VERSION ""

NS_ :

BS_:

BU_: Reserve2 SS_WT4 SS_WT3 SS_WT2 SS_WT1 SS_WP2 SS_WP1 SS_WF SS_SA SS_RTDS SS_DFR SS_DFL SS_DBR SS_DBL VCU User Reserve1 Telemetry SteeringWheel SS_BL SmartSensor PIC ISA_Scale Distri Dashboard AMS AclrGPS
VAL_TABLE_ AliveSignal 1 "ONLINE" 0 "OFFLINE" ;

BO_ 512 AMS_Status: 5 AMS
 SG_ Cell_OV_288 m23 : 39|1@0+ (1,0) [0|0] ""  VCU
 SG_ Cell_UV_288 m23 : 38|1@0+ (1,0) [0|0] ""  VCU
 SG_ Cell_OV_287 m23 : 37|1@0+ (1,0) [0|0] ""  VCU
 SG_ Cell_UV_287 m23 : 36|1@0+ (1,0) [0|0] ""  VCU
 SG_ Cell_OV_286 m23 : 35|1@0+ (1,0) [0|0] ""  VCU
 SG_ Cell_UV_286 m23 : 34|1@0+ (1,0) [0|0] ""  VCU
 SG_ Cell_OV_285 m23 : 33|1@0+ (1,0) [0|0] ""  VCU
 SG_ Cell_UV_285 m23 : 32|1@0+ (1,0) [0|0] ""  VCU
 SG_ Cell_OV_284 m23 : 31|1@0+ (1,0) [0|0] ""  VCU
 SG_ Cell_UV_284 m23 : 30|1@0+ (1,0) [0|0] ""  VCU
 SG_ Cell_OV_283 m23 : 29|1@0+ (1,0) [0|0] ""  VCU
 SG_ Cell_UV_283 m23 : 28|1@0+ (1,0) [0|0] ""  VCU
 SG_ Cell_OV_282 m23 : 27|1@0+ (1,0) [0|0] ""  VCU
 SG_ Cell_UV_282 m23 : 26|1@0+ (1,0) [0|0] ""  VCU
 SG_ Cell_OV_281 m23 : 25|1@0+ (1,0) [0|0] ""  VCU
 SG_ Cell_UV_281 m23 : 24|1@0+ (1,0) [0|0] ""  VCU
 SG_ Cell_OV_280 m23 : 23|1@0+ (1,0) [0|0] ""  VCU
 SG_ Cell_UV_280 m23 : 22|1@0+ (1,0) [0|0] ""  VCU
 SG_ Cell_OV_279 m23 : 21|1@0+ (1,0) [0|0] ""  VCU
 SG_ Cell_UV_279 m23 : 20|1@0+ (1,0) [0|0] ""  VCU
 SG_ Cell_OV_278 m23 : 19|1@0+ (1,0) [0|0] ""  VCU
 SG_ Cell_UV_278 m23 : 18|1@0+ (1,0) [0|0] ""  VCU
 SG_ Cell_OV_277 m23 : 17|1@0+ (1,0) [0|0] ""  VCU
 SG_ Cell_UV_277 m23 : 16|1@0+ (1,0) [0|0] ""  VCU
 SG_ Cell_OV_276 m22 : 39|1@0+ (1,0) [0|0] ""  VCU
 SG_ Cell_UV_276 m22 : 38|1@0+ (1,0) [0|0] ""  VCU
 SG_ Cell_OV_275 m22 : 37|1@0+ (1,0) [0|0] ""  VCU
 SG_ Cell_UV_275 m22 : 36|1@0+ (1,0) [0|0] ""  VCU
 SG_ Cell_OV_274 m22 : 35|1@0+ (1,0) [0|0] ""  VCU
 SG_ Cell_UV_274 m22 : 34|1@0+ (1,0) [0|0] ""  VCU
 SG_ Cell_OV_273 m22 : 33|1@0+ (1,0) [0|0] ""  VCU
 SG_ Cell_UV_273 m22 : 32|1@0+ (1,0) [0|0] ""  VCU
 SG_ Cell_OV_272 m22 : 31|1@0+ (1,0) [0|0] ""  VCU
 SG_ Cell_UV_272 m22 : 30|1@0+ (1,0) [0|0] ""  VCU
 SG_ Cell_OV_271 m22 : 29|1@0+ (1,0) [0|0] ""  VCU
 SG_ Cell_UV_271 m22 : 28|1@0+ (1,0) [0|0] ""  VCU
 SG_ Cell_OV_270 m22 : 27|1@0+ (1,0) [0|0] ""  VCU
 SG_ Cell_UV_270 m22 : 26|1@0+ (1,0) [0|0] ""  VCU
 SG_ Cell_OV_269 m22 : 25|1@0+ (1,0) [0|0] ""  VCU
 SG_ Cell_UV_269 m22 : 24|1@0+ (1,0) [0|0] ""  VCU
 SG_ Cell_OV_268 m22 : 23|1@0+ (1,0) [0|0] ""  VCU
 SG_ Cell_UV_268 m22 : 22|1@0+ (1,0) [0|0] ""  VCU
 SG_ Cell_OV_267 m22 : 21|1@0+ (1,0) [0|0] ""  VCU
 SG_ Cell_UV_267 m22 : 20|1@0+ (1,0) [0|0] ""  VCU
 SG_ Cell_OV_266 m22 : 19|1@0+ (1,0) [0|0] ""  VCU
 SG_ Cell_UV_266 m22 : 18|1@0+ (1,0) [0|0] ""  VCU
 SG_ Cell_OV_265 m22 : 17|1@0+ (1,0) [0|0] ""  VCU
 SG_ Cell_UV_265 m22 : 16|1@0+ (1,0) [0|0] ""  VCU
 SG_ Cell_OV_264 m21 : 39|1@0+ (1,0) [0|0] ""  VCU
 SG_ Cell_UV_264 m21 : 38|1@0+ (1,0) [0|0] ""  VCU
 SG_ Cell_OV_263 m21 : 37|1@0+ (1,0) [0|0] ""  VCU
 SG_ Cell_UV_263 m21 : 36|1@0+ (1,0) [0|0] ""  VCU
 SG_ Cell_OV_262 m21 : 35|1@0+ (1,0) [0|0] ""  VCU
 SG_ Cell_UV_262 m21 : 34|1@0+ (1,0) [0|0] ""  VCU
 SG_ Cell_OV_261 m21 : 33|1@0+ (1,0) [0|0] ""  VCU
 SG_ Cell_UV_261 m21 : 32|1@0+ (1,0) [0|0] ""  VCU
 SG_ Cell_OV_260 m21 : 31|1@0+ (1,0) [0|0] ""  VCU
 SG_ Cell_UV_260 m21 : 30|1@0+ (1,0) [0|0] ""  VCU
 SG_ Cell_OV_259 m21 : 29|1@0+ (1,0) [0|0] ""  VCU
 SG_ Cell_UV_259 m21 : 28|1@0+ (1,0) [0|0] ""  VCU
 SG_ Cell_OV_258 m21 : 27|1@0+ (1,0) [0|0] ""  VCU
 SG_ Cell_UV_258 m21 : 26|1@0+ (1,0) [0|0] ""  VCU
 SG_ Cell_OV_257 m21 : 25|1@0+ (1,0) [0|0] ""  VCU
 SG_ Cell_UV_257 m21 : 24|1@0+ (1,0) [0|0] ""  VCU
 SG_ Cell_OV_256 m21 : 23|1@0+ (1,0) [0|0] ""  VCU
 SG_ Cell_UV_256 m21 : 22|1@0+ (1,0) [0|0] ""  VCU
 SG_ Cell_OV_255 m21 : 21|1@0+ (1,0) [0|0] ""  VCU
 SG_ Cell_UV_255 m21 : 20|1@0+ (1,0) [0|0] ""  VCU
 SG_ Cell_OV_254 m21 : 19|1@0+ (1,0) [0|0] ""  VCU
 SG_ Cell_UV_254 m21 : 18|1@0+ (1,0) [0|0] ""  VCU
 SG_ Cell_OV_253 m21 : 17|1@0+ (1,0) [0|0] ""  VCU
 SG_ Cell_UV_253 m21 : 16|1@0+ (1,0) [0|0] ""  VCU
 SG_ Cell_OV_252 m20 : 39|1@0+ (1,0) [0|0] ""  VCU
 SG_ Cell_UV_252 m20 : 38|1@0+ (1,0) [0|0] ""  VCU
 SG_ Cell_OV_251 m20 : 37|1@0+ (1,0) [0|0] ""  VCU
 SG_ Cell_UV_251 m20 : 36|1@0+ (1,0) [0|0] ""  VCU
 SG_ Cell_OV_250 m20 : 35|1@0+ (1,0) [0|0] ""  VCU
 SG_ Cell_UV_250 m20 : 34|1@0+ (1,0) [0|0] ""  VCU
 SG_ Cell_OV_249 m20 : 33|1@0+ (1,0) [0|0] ""  VCU
 SG_ Cell_UV_249 m20 : 32|1@0+ (1,0) [0|0] ""  VCU
 SG_ Cell_OV_248 m20 : 31|1@0+ (1,0) [0|0] ""  VCU
 SG_ Cell_UV_248 m20 : 30|1@0+ (1,0) [0|0] ""  VCU
 SG_ Cell_OV_247 m20 : 29|1@0+ (1,0) [0|0] ""  VCU
 SG_ Cell_UV_247 m20 : 28|1@0+ (1,0) [0|0] ""  VCU
 SG_ Cell_OV_246 m20 : 27|1@0+ (1,0) [0|0] ""  VCU
 SG_ Cell_UV_246 m20 : 26|1@0+ (1,0) [0|0] ""  VCU
 SG_ Cell_OV_245 m20 : 25|1@0+ (1,0) [0|0] ""  VCU
 SG_ Cell_UV_245 m20 : 24|1@0+ (1,0) [0|0] ""  VCU
 SG_ Cell_OV_244 m20 : 23|1@0+ (1,0) [0|0] ""  VCU
 SG_ Cell_UV_244 m20 : 22|1@0+ (1,0) [0|0] ""  VCU
 SG_ Cell_OV_243 m20 : 21|1@0+ (1,0) [0|0] ""  VCU
 SG_ Cell_UV_243 m20 : 20|1@0+ (1,0) [0|0] ""  VCU
 SG_ Cell_OV_242 m20 : 19|1@0+ (1,0) [0|0] ""  VCU
 SG_ Cell_UV_242 m20 : 18|1@0+ (1,0) [0|0] ""  VCU
 SG_ Cell_OV_241 m20 : 17|1@0+ (1,0) [0|0] ""  VCU
 SG_ Cell_UV_241 m20 : 16|1@0+ (1,0) [0|0] ""  VCU
 SG_ Cell_OV_240 m19 : 39|1@0+ (1,0) [0|0] ""  VCU
 SG_ Cell_UV_240 m19 : 38|1@0+ (1,0) [0|0] ""  VCU
 SG_ Cell_OV_239 m19 : 37|1@0+ (1,0) [0|0] ""  VCU
 SG_ Cell_UV_239 m19 : 36|1@0+ (1,0) [0|0] ""  VCU
 SG_ Cell_OV_238 m19 : 35|1@0+ (1,0) [0|0] ""  VCU
 SG_ Cell_UV_238 m19 : 34|1@0+ (1,0) [0|0] ""  VCU
 SG_ Cell_OV_237 m19 : 33|1@0+ (1,0) [0|0] ""  VCU
 SG_ Cell_UV_237 m19 : 32|1@0+ (1,0) [0|0] ""  VCU
 SG_ Cell_OV_236 m19 : 31|1@0+ (1,0) [0|0] ""  VCU
 SG_ Cell_UV_236 m19 : 30|1@0+ (1,0) [0|0] ""  VCU
 SG_ Cell_OV_235 m19 : 29|1@0+ (1,0) [0|0] ""  VCU
 SG_ Cell_UV_235 m19 : 28|1@0+ (1,0) [0|0] ""  VCU
 SG_ Cell_OV_234 m19 : 27|1@0+ (1,0) [0|0] ""  VCU
 SG_ Cell_UV_234 m19 : 26|1@0+ (1,0) [0|0] ""  VCU
 SG_ Cell_OV_233 m19 : 25|1@0+ (1,0) [0|0] ""  VCU
 SG_ Cell_UV_233 m19 : 24|1@0+ (1,0) [0|0] ""  VCU
 SG_ Cell_OV_232 m19 : 23|1@0+ (1,0) [0|0] ""  VCU
 SG_ Cell_UV_232 m19 : 22|1@0+ (1,0) [0|0] ""  VCU
 SG_ Cell_OV_231 m19 : 21|1@0+ (1,0) [0|0] ""  VCU
 SG_ Cell_UV_231 m19 : 20|1@0+ (1,0) [0|0] ""  VCU
 SG_ Cell_OV_230 m19 : 19|1@0+ (1,0) [0|0] ""  VCU
 SG_ Cell_UV_230 m19 : 18|1@0+ (1,0) [0|0] ""  VCU
 SG_ Cell_OV_229 m19 : 17|1@0+ (1,0) [0|0] ""  VCU
 SG_ Cell_UV_229 m19 : 16|1@0+ (1,0) [0|0] ""  VCU
 SG_ Cell_OV_228 m18 : 39|1@0+ (1,0) [0|0] ""  VCU
 SG_ Cell_UV_228 m18 : 38|1@0+ (1,0) [0|0] ""  VCU
 SG_ Cell_OV_227 m18 : 37|1@0+ (1,0) [0|0] ""  VCU
 SG_ Cell_UV_227 m18 : 36|1@0+ (1,0) [0|0] ""  VCU
 SG_ Cell_OV_226 m18 : 35|1@0+ (1,0) [0|0] ""  VCU
 SG_ Cell_UV_226 m18 : 34|1@0+ (1,0) [0|0] ""  VCU
 SG_ Cell_OV_225 m18 : 33|1@0+ (1,0) [0|0] ""  VCU
 SG_ Cell_UV_225 m18 : 32|1@0+ (1,0) [0|0] ""  VCU
 SG_ Cell_OV_224 m18 : 31|1@0+ (1,0) [0|0] ""  VCU
 SG_ Cell_UV_224 m18 : 30|1@0+ (1,0) [0|0] ""  VCU
 SG_ Cell_OV_223 m18 : 29|1@0+ (1,0) [0|0] ""  VCU
 SG_ Cell_UV_223 m18 : 28|1@0+ (1,0) [0|0] ""  VCU
 SG_ Cell_OV_222 m18 : 27|1@0+ (1,0) [0|0] ""  VCU
 SG_ Cell_UV_222 m18 : 26|1@0+ (1,0) [0|0] ""  VCU
 SG_ Cell_OV_221 m18 : 25|1@0+ (1,0) [0|0] ""  VCU
 SG_ Cell_UV_221 m18 : 24|1@0+ (1,0) [0|0] ""  VCU
 SG_ Cell_OV_220 m18 : 23|1@0+ (1,0) [0|0] ""  VCU
 SG_ Cell_UV_220 m18 : 22|1@0+ (1,0) [0|0] ""  VCU
 SG_ Cell_OV_219 m18 : 21|1@0+ (1,0) [0|0] ""  VCU
 SG_ Cell_UV_219 m18 : 20|1@0+ (1,0) [0|0] ""  VCU
 SG_ Cell_OV_218 m18 : 19|1@0+ (1,0) [0|0] ""  VCU
 SG_ Cell_UV_218 m18 : 18|1@0+ (1,0) [0|0] ""  VCU
 SG_ Cell_OV_217 m18 : 17|1@0+ (1,0) [0|0] ""  VCU
 SG_ Cell_UV_217 m18 : 16|1@0+ (1,0) [0|0] ""  VCU
 SG_ Cell_OV_216 m17 : 39|1@0+ (1,0) [0|0] ""  VCU
 SG_ Cell_UV_216 m17 : 38|1@0+ (1,0) [0|0] ""  VCU
 SG_ Cell_OV_215 m17 : 37|1@0+ (1,0) [0|0] ""  VCU
 SG_ Cell_UV_215 m17 : 36|1@0+ (1,0) [0|0] ""  VCU
 SG_ Cell_OV_214 m17 : 35|1@0+ (1,0) [0|0] ""  VCU
 SG_ Cell_UV_214 m17 : 34|1@0+ (1,0) [0|0] ""  VCU
 SG_ Cell_OV_213 m17 : 33|1@0+ (1,0) [0|0] ""  VCU
 SG_ Cell_UV_213 m17 : 32|1@0+ (1,0) [0|0] ""  VCU
 SG_ Cell_OV_212 m17 : 31|1@0+ (1,0) [0|0] ""  VCU
 SG_ Cell_UV_212 m17 : 30|1@0+ (1,0) [0|0] ""  VCU
 SG_ Cell_OV_211 m17 : 29|1@0+ (1,0) [0|0] ""  VCU
 SG_ Cell_UV_211 m17 : 28|1@0+ (1,0) [0|0] ""  VCU
 SG_ Cell_OV_210 m17 : 27|1@0+ (1,0) [0|0] ""  VCU
 SG_ Cell_UV_210 m17 : 26|1@0+ (1,0) [0|0] ""  VCU
 SG_ Cell_OV_209 m17 : 25|1@0+ (1,0) [0|0] ""  VCU
 SG_ Cell_UV_209 m17 : 24|1@0+ (1,0) [0|0] ""  VCU
 SG_ Cell_OV_208 m17 : 23|1@0+ (1,0) [0|0] ""  VCU
 SG_ Cell_UV_208 m17 : 22|1@0+ (1,0) [0|0] ""  VCU
 SG_ Cell_OV_207 m17 : 21|1@0+ (1,0) [0|0] ""  VCU
 SG_ Cell_UV_207 m17 : 20|1@0+ (1,0) [0|0] ""  VCU
 SG_ Cell_OV_206 m17 : 19|1@0+ (1,0) [0|0] ""  VCU
 SG_ Cell_UV_206 m17 : 18|1@0+ (1,0) [0|0] ""  VCU
 SG_ Cell_OV_205 m17 : 17|1@0+ (1,0) [0|0] ""  VCU
 SG_ Cell_UV_205 m17 : 16|1@0+ (1,0) [0|0] ""  VCU
 SG_ Cell_OV_204 m16 : 39|1@0+ (1,0) [0|0] ""  VCU
 SG_ Cell_UV_204 m16 : 38|1@0+ (1,0) [0|0] ""  VCU
 SG_ Cell_OV_203 m16 : 37|1@0+ (1,0) [0|0] ""  VCU
 SG_ Cell_UV_203 m16 : 36|1@0+ (1,0) [0|0] ""  VCU
 SG_ Cell_OV_202 m16 : 35|1@0+ (1,0) [0|0] ""  VCU
 SG_ Cell_UV_202 m16 : 34|1@0+ (1,0) [0|0] ""  VCU
 SG_ Cell_OV_201 m16 : 33|1@0+ (1,0) [0|0] ""  VCU
 SG_ Cell_UV_201 m16 : 32|1@0+ (1,0) [0|0] ""  VCU
 SG_ Cell_OV_200 m16 : 31|1@0+ (1,0) [0|0] ""  VCU
 SG_ Cell_UV_200 m16 : 30|1@0+ (1,0) [0|0] ""  VCU
 SG_ Cell_OV_199 m16 : 29|1@0+ (1,0) [0|0] ""  VCU
 SG_ Cell_UV_199 m16 : 28|1@0+ (1,0) [0|0] ""  VCU
 SG_ Cell_OV_198 m16 : 27|1@0+ (1,0) [0|0] ""  VCU
 SG_ Cell_UV_198 m16 : 26|1@0+ (1,0) [0|0] ""  VCU
 SG_ Cell_OV_197 m16 : 25|1@0+ (1,0) [0|0] ""  VCU
 SG_ Cell_UV_197 m16 : 24|1@0+ (1,0) [0|0] ""  VCU
 SG_ Cell_OV_196 m16 : 23|1@0+ (1,0) [0|0] ""  VCU
 SG_ Cell_UV_196 m16 : 22|1@0+ (1,0) [0|0] ""  VCU
 SG_ Cell_OV_195 m16 : 21|1@0+ (1,0) [0|0] ""  VCU
 SG_ Cell_UV_195 m16 : 20|1@0+ (1,0) [0|0] ""  VCU
 SG_ Cell_OV_194 m16 : 19|1@0+ (1,0) [0|0] ""  VCU
 SG_ Cell_UV_194 m16 : 18|1@0+ (1,0) [0|0] ""  VCU
 SG_ Cell_OV_193 m16 : 17|1@0+ (1,0) [0|0] ""  VCU
 SG_ Cell_UV_193 m16 : 16|1@0+ (1,0) [0|0] ""  VCU
 SG_ Cell_OV_192 m15 : 39|1@0+ (1,0) [0|0] ""  VCU
 SG_ Cell_UV_192 m15 : 38|1@0+ (1,0) [0|0] ""  VCU
 SG_ Cell_OV_191 m15 : 37|1@0+ (1,0) [0|0] ""  VCU
 SG_ Cell_UV_191 m15 : 36|1@0+ (1,0) [0|0] ""  VCU
 SG_ Cell_OV_190 m15 : 35|1@0+ (1,0) [0|0] ""  VCU
 SG_ Cell_UV_190 m15 : 34|1@0+ (1,0) [0|0] ""  VCU
 SG_ Cell_OV_189 m15 : 33|1@0+ (1,0) [0|0] ""  VCU
 SG_ Cell_UV_189 m15 : 32|1@0+ (1,0) [0|0] ""  VCU
 SG_ Cell_OV_188 m15 : 31|1@0+ (1,0) [0|0] ""  VCU
 SG_ Cell_UV_188 m15 : 30|1@0+ (1,0) [0|0] ""  VCU
 SG_ Cell_OV_187 m15 : 29|1@0+ (1,0) [0|0] ""  VCU
 SG_ Cell_UV_187 m15 : 28|1@0+ (1,0) [0|0] ""  VCU
 SG_ Cell_OV_186 m15 : 27|1@0+ (1,0) [0|0] ""  VCU
 SG_ Cell_UV_186 m15 : 26|1@0+ (1,0) [0|0] ""  VCU
 SG_ Cell_OV_185 m15 : 25|1@0+ (1,0) [0|0] ""  VCU
 SG_ Cell_UV_185 m15 : 24|1@0+ (1,0) [0|0] ""  VCU
 SG_ Cell_OV_184 m15 : 23|1@0+ (1,0) [0|0] ""  VCU
 SG_ Cell_UV_184 m15 : 22|1@0+ (1,0) [0|0] ""  VCU
 SG_ Cell_OV_183 m15 : 21|1@0+ (1,0) [0|0] ""  VCU
 SG_ Cell_UV_183 m15 : 20|1@0+ (1,0) [0|0] ""  VCU
 SG_ Cell_OV_182 m15 : 19|1@0+ (1,0) [0|0] ""  VCU
 SG_ Cell_UV_182 m15 : 18|1@0+ (1,0) [0|0] ""  VCU
 SG_ Cell_OV_181 m15 : 17|1@0+ (1,0) [0|0] ""  VCU
 SG_ Cell_UV_181 m15 : 16|1@0+ (1,0) [0|0] ""  VCU
 SG_ Cell_OV_180 m14 : 39|1@0+ (1,0) [0|0] ""  VCU
 SG_ Cell_UV_180 m14 : 38|1@0+ (1,0) [0|0] ""  VCU
 SG_ Cell_OV_179 m14 : 37|1@0+ (1,0) [0|0] ""  VCU
 SG_ Cell_UV_179 m14 : 36|1@0+ (1,0) [0|0] ""  VCU
 SG_ Cell_OV_178 m14 : 35|1@0+ (1,0) [0|0] ""  VCU
 SG_ Cell_UV_178 m14 : 34|1@0+ (1,0) [0|0] ""  VCU
 SG_ Cell_OV_177 m14 : 33|1@0+ (1,0) [0|0] ""  VCU
 SG_ Cell_UV_177 m14 : 32|1@0+ (1,0) [0|0] ""  VCU
 SG_ Cell_OV_176 m14 : 31|1@0+ (1,0) [0|0] ""  VCU
 SG_ Cell_UV_176 m14 : 30|1@0+ (1,0) [0|0] ""  VCU
 SG_ Cell_OV_175 m14 : 29|1@0+ (1,0) [0|0] ""  VCU
 SG_ Cell_UV_175 m14 : 28|1@0+ (1,0) [0|0] ""  VCU
 SG_ Cell_OV_174 m14 : 27|1@0+ (1,0) [0|0] ""  VCU
 SG_ Cell_UV_174 m14 : 26|1@0+ (1,0) [0|0] ""  VCU
 SG_ Cell_OV_173 m14 : 25|1@0+ (1,0) [0|0] ""  VCU
 SG_ Cell_UV_173 m14 : 24|1@0+ (1,0) [0|0] ""  VCU
 SG_ Cell_OV_172 m14 : 23|1@0+ (1,0) [0|0] ""  VCU
 SG_ Cell_UV_172 m14 : 22|1@0+ (1,0) [0|0] ""  VCU
 SG_ Cell_OV_171 m14 : 21|1@0+ (1,0) [0|0] ""  VCU
 SG_ Cell_UV_171 m14 : 20|1@0+ (1,0) [0|0] ""  VCU
 SG_ Cell_OV_170 m14 : 19|1@0+ (1,0) [0|0] ""  VCU
 SG_ Cell_UV_170 m14 : 18|1@0+ (1,0) [0|0] ""  VCU
 SG_ Cell_OV_169 m14 : 17|1@0+ (1,0) [0|0] ""  VCU
 SG_ Cell_UV_169 m14 : 16|1@0+ (1,0) [0|0] ""  VCU
 SG_ Cell_OV_168 m13 : 39|1@0+ (1,0) [0|0] ""  VCU
 SG_ Cell_UV_168 m13 : 38|1@0+ (1,0) [0|0] ""  VCU
 SG_ Cell_OV_167 m13 : 37|1@0+ (1,0) [0|0] ""  VCU
 SG_ Cell_UV_167 m13 : 36|1@0+ (1,0) [0|0] ""  VCU
 SG_ Cell_OV_166 m13 : 35|1@0+ (1,0) [0|0] ""  VCU
 SG_ Cell_UV_166 m13 : 34|1@0+ (1,0) [0|0] ""  VCU
 SG_ Cell_OV_165 m13 : 33|1@0+ (1,0) [0|0] ""  VCU
 SG_ Cell_UV_165 m13 : 32|1@0+ (1,0) [0|0] ""  VCU
 SG_ Cell_OV_164 m13 : 31|1@0+ (1,0) [0|0] ""  VCU
 SG_ Cell_UV_164 m13 : 30|1@0+ (1,0) [0|0] ""  VCU
 SG_ Cell_OV_163 m13 : 29|1@0+ (1,0) [0|0] ""  VCU
 SG_ Cell_UV_163 m13 : 28|1@0+ (1,0) [0|0] ""  VCU
 SG_ Cell_OV_162 m13 : 27|1@0+ (1,0) [0|0] ""  VCU
 SG_ Cell_UV_162 m13 : 26|1@0+ (1,0) [0|0] ""  VCU
 SG_ Cell_OV_161 m13 : 25|1@0+ (1,0) [0|0] ""  VCU
 SG_ Cell_UV_161 m13 : 24|1@0+ (1,0) [0|0] ""  VCU
 SG_ Cell_OV_160 m13 : 23|1@0+ (1,0) [0|0] ""  VCU
 SG_ Cell_UV_160 m13 : 22|1@0+ (1,0) [0|0] ""  VCU
 SG_ Cell_OV_159 m13 : 21|1@0+ (1,0) [0|0] ""  VCU
 SG_ Cell_UV_159 m13 : 20|1@0+ (1,0) [0|0] ""  VCU
 SG_ Cell_OV_158 m13 : 19|1@0+ (1,0) [0|0] ""  VCU
 SG_ Cell_UV_158 m13 : 18|1@0+ (1,0) [0|0] ""  VCU
 SG_ Cell_OV_157 m13 : 17|1@0+ (1,0) [0|0] ""  VCU
 SG_ Cell_UV_157 m13 : 16|1@0+ (1,0) [0|0] ""  VCU
 SG_ Cell_OV_156 m12 : 39|1@0+ (1,0) [0|0] ""  VCU
 SG_ Cell_UV_156 m12 : 38|1@0+ (1,0) [0|0] ""  VCU
 SG_ Cell_OV_155 m12 : 37|1@0+ (1,0) [0|0] ""  VCU
 SG_ Cell_UV_155 m12 : 36|1@0+ (1,0) [0|0] ""  VCU
 SG_ Cell_OV_154 m12 : 35|1@0+ (1,0) [0|0] ""  VCU
 SG_ Cell_UV_154 m12 : 34|1@0+ (1,0) [0|0] ""  VCU
 SG_ Cell_OV_153 m12 : 33|1@0+ (1,0) [0|0] ""  VCU
 SG_ Cell_UV_153 m12 : 32|1@0+ (1,0) [0|0] ""  VCU
 SG_ Cell_OV_152 m12 : 31|1@0+ (1,0) [0|0] ""  VCU
 SG_ Cell_UV_152 m12 : 30|1@0+ (1,0) [0|0] ""  VCU
 SG_ Cell_OV_151 m12 : 29|1@0+ (1,0) [0|0] ""  VCU
 SG_ Cell_UV_151 m12 : 28|1@0+ (1,0) [0|0] ""  VCU
 SG_ Cell_OV_150 m12 : 27|1@0+ (1,0) [0|0] ""  VCU
 SG_ Cell_UV_150 m12 : 26|1@0+ (1,0) [0|0] ""  VCU
 SG_ Cell_OV_149 m12 : 25|1@0+ (1,0) [0|0] ""  VCU
 SG_ Cell_UV_149 m12 : 24|1@0+ (1,0) [0|0] ""  VCU
 SG_ Cell_OV_148 m12 : 23|1@0+ (1,0) [0|0] ""  VCU
 SG_ Cell_UV_148 m12 : 22|1@0+ (1,0) [0|0] ""  VCU
 SG_ Cell_OV_147 m12 : 21|1@0+ (1,0) [0|0] ""  VCU
 SG_ Cell_UV_147 m12 : 20|1@0+ (1,0) [0|0] ""  VCU
 SG_ Cell_OV_146 m12 : 19|1@0+ (1,0) [0|0] ""  VCU
 SG_ Cell_UV_146 m12 : 18|1@0+ (1,0) [0|0] ""  VCU
 SG_ Cell_OV_145 m12 : 17|1@0+ (1,0) [0|0] ""  VCU
 SG_ Cell_UV_145 m12 : 16|1@0+ (1,0) [0|0] ""  VCU
 SG_ Cell_UV_144 m11 : 38|1@0+ (1,0) [0|0] ""  VCU
 SG_ Cell_UV_143 m11 : 36|1@0+ (1,0) [0|0] ""  VCU
 SG_ Cell_UV_142 m11 : 34|1@0+ (1,0) [0|0] ""  VCU
 SG_ Cell_UV_141 m11 : 32|1@0+ (1,0) [0|0] ""  VCU
 SG_ Cell_UV_140 m11 : 30|1@0+ (1,0) [0|0] ""  VCU
 SG_ Cell_UV_139 m11 : 28|1@0+ (1,0) [0|0] ""  VCU
 SG_ Cell_UV_138 m11 : 26|1@0+ (1,0) [0|0] ""  VCU
 SG_ Cell_UV_137 m11 : 24|1@0+ (1,0) [0|0] ""  VCU
 SG_ Cell_UV_136 m11 : 22|1@0+ (1,0) [0|0] ""  VCU
 SG_ Cell_UV_135 m11 : 20|1@0+ (1,0) [0|0] ""  VCU
 SG_ Cell_UV_134 m11 : 18|1@0+ (1,0) [0|0] ""  VCU
 SG_ Cell_UV_133 m11 : 16|1@0+ (1,0) [0|0] ""  VCU
 SG_ Cell_OV_144 m11 : 39|1@0+ (1,0) [0|0] ""  VCU
 SG_ Cell_OV_143 m11 : 37|1@0+ (1,0) [0|0] ""  VCU
 SG_ Cell_OV_142 m11 : 35|1@0+ (1,0) [0|0] ""  VCU
 SG_ Cell_OV_141 m11 : 33|1@0+ (1,0) [0|0] ""  VCU
 SG_ Cell_OV_140 m11 : 31|1@0+ (1,0) [0|0] ""  VCU
 SG_ Cell_OV_139 m11 : 29|1@0+ (1,0) [0|0] ""  VCU
 SG_ Cell_OV_138 m11 : 27|1@0+ (1,0) [0|0] ""  VCU
 SG_ Cell_OV_137 m11 : 25|1@0+ (1,0) [0|0] ""  VCU
 SG_ Cell_OV_136 m11 : 23|1@0+ (1,0) [0|0] ""  VCU
 SG_ Cell_OV_135 m11 : 21|1@0+ (1,0) [0|0] ""  VCU
 SG_ Cell_OV_134 m11 : 19|1@0+ (1,0) [0|0] ""  VCU
 SG_ Cell_OV_133 m11 : 17|1@0+ (1,0) [0|0] ""  VCU
 SG_ Cell_UV_132 m10 : 38|1@0+ (1,0) [0|0] ""  VCU
 SG_ Cell_UV_131 m10 : 36|1@0+ (1,0) [0|0] ""  VCU
 SG_ Cell_UV_130 m10 : 34|1@0+ (1,0) [0|0] ""  VCU
 SG_ Cell_UV_129 m10 : 32|1@0+ (1,0) [0|0] ""  VCU
 SG_ Cell_UV_128 m10 : 30|1@0+ (1,0) [0|0] ""  VCU
 SG_ Cell_UV_127 m10 : 28|1@0+ (1,0) [0|0] ""  VCU
 SG_ Cell_UV_126 m10 : 26|1@0+ (1,0) [0|0] ""  VCU
 SG_ Cell_UV_125 m10 : 24|1@0+ (1,0) [0|0] ""  VCU
 SG_ Cell_UV_124 m10 : 22|1@0+ (1,0) [0|0] ""  VCU
 SG_ Cell_UV_123 m10 : 20|1@0+ (1,0) [0|0] ""  VCU
 SG_ Cell_UV_122 m10 : 18|1@0+ (1,0) [0|0] ""  VCU
 SG_ Cell_UV_121 m10 : 16|1@0+ (1,0) [0|0] ""  VCU
 SG_ Cell_OV_132 m10 : 39|1@0+ (1,0) [0|0] ""  VCU
 SG_ Cell_OV_131 m10 : 37|1@0+ (1,0) [0|0] ""  VCU
 SG_ Cell_OV_130 m10 : 35|1@0+ (1,0) [0|0] ""  VCU
 SG_ Cell_OV_129 m10 : 33|1@0+ (1,0) [0|0] ""  VCU
 SG_ Cell_OV_128 m10 : 31|1@0+ (1,0) [0|0] ""  VCU
 SG_ Cell_OV_127 m10 : 29|1@0+ (1,0) [0|0] ""  VCU
 SG_ Cell_OV_126 m10 : 27|1@0+ (1,0) [0|0] ""  VCU
 SG_ Cell_OV_125 m10 : 25|1@0+ (1,0) [0|0] ""  VCU
 SG_ Cell_OV_124 m10 : 23|1@0+ (1,0) [0|0] ""  VCU
 SG_ Cell_OV_123 m10 : 21|1@0+ (1,0) [0|0] ""  VCU
 SG_ Cell_OV_122 m10 : 19|1@0+ (1,0) [0|0] ""  VCU
 SG_ Cell_OV_121 m10 : 17|1@0+ (1,0) [0|0] ""  VCU
 SG_ Cell_UV_120 m9 : 38|1@0+ (1,0) [0|0] ""  VCU
 SG_ Cell_UV_119 m9 : 36|1@0+ (1,0) [0|0] ""  VCU
 SG_ Cell_UV_118 m9 : 34|1@0+ (1,0) [0|0] ""  VCU
 SG_ Cell_UV_117 m9 : 32|1@0+ (1,0) [0|0] ""  VCU
 SG_ Cell_UV_116 m9 : 30|1@0+ (1,0) [0|0] ""  VCU
 SG_ Cell_UV_115 m9 : 28|1@0+ (1,0) [0|0] ""  VCU
 SG_ Cell_UV_114 m9 : 26|1@0+ (1,0) [0|0] ""  VCU
 SG_ Cell_UV_113 m9 : 24|1@0+ (1,0) [0|0] ""  VCU
 SG_ Cell_UV_112 m9 : 22|1@0+ (1,0) [0|0] ""  VCU
 SG_ Cell_UV_111 m9 : 20|1@0+ (1,0) [0|0] ""  VCU
 SG_ Cell_UV_110 m9 : 18|1@0+ (1,0) [0|0] ""  VCU
 SG_ Cell_UV_109 m9 : 16|1@0+ (1,0) [0|0] ""  VCU
 SG_ Cell_OV_120 m9 : 39|1@0+ (1,0) [0|0] ""  VCU
 SG_ Cell_OV_119 m9 : 37|1@0+ (1,0) [0|0] ""  VCU
 SG_ Cell_OV_118 m9 : 35|1@0+ (1,0) [0|0] ""  VCU
 SG_ Cell_OV_117 m9 : 33|1@0+ (1,0) [0|0] ""  VCU
 SG_ Cell_OV_116 m9 : 31|1@0+ (1,0) [0|0] ""  VCU
 SG_ Cell_OV_115 m9 : 29|1@0+ (1,0) [0|0] ""  VCU
 SG_ Cell_OV_114 m9 : 27|1@0+ (1,0) [0|0] ""  VCU
 SG_ Cell_OV_113 m9 : 25|1@0+ (1,0) [0|0] ""  VCU
 SG_ Cell_OV_112 m9 : 23|1@0+ (1,0) [0|0] ""  VCU
 SG_ Cell_OV_111 m9 : 21|1@0+ (1,0) [0|0] ""  VCU
 SG_ Cell_OV_110 m9 : 19|1@0+ (1,0) [0|0] ""  VCU
 SG_ Cell_OV_109 m9 : 17|1@0+ (1,0) [0|0] ""  VCU
 SG_ Cell_OV_108 m8 : 39|1@0+ (1,0) [0|0] ""  VCU
 SG_ Cell_UV_108 m8 : 38|1@0+ (1,0) [0|0] ""  VCU
 SG_ Cell_OV_107 m8 : 37|1@0+ (1,0) [0|0] ""  VCU
 SG_ Cell_UV_107 m8 : 36|1@0+ (1,0) [0|0] ""  VCU
 SG_ Cell_OV_106 m8 : 35|1@0+ (1,0) [0|0] ""  VCU
 SG_ Cell_UV_106 m8 : 34|1@0+ (1,0) [0|0] ""  VCU
 SG_ Cell_OV_105 m8 : 33|1@0+ (1,0) [0|0] ""  VCU
 SG_ Cell_UV_105 m8 : 32|1@0+ (1,0) [0|0] ""  VCU
 SG_ Cell_OV_104 m8 : 31|1@0+ (1,0) [0|0] ""  VCU
 SG_ Cell_UV_104 m8 : 30|1@0+ (1,0) [0|0] ""  VCU
 SG_ Cell_OV_103 m8 : 29|1@0+ (1,0) [0|0] ""  VCU
 SG_ Cell_UV_103 m8 : 28|1@0+ (1,0) [0|0] ""  VCU
 SG_ Cell_OV_102 m8 : 27|1@0+ (1,0) [0|0] ""  VCU
 SG_ Cell_UV_102 m8 : 26|1@0+ (1,0) [0|0] ""  VCU
 SG_ Cell_OV_101 m8 : 25|1@0+ (1,0) [0|0] ""  VCU
 SG_ Cell_UV_101 m8 : 24|1@0+ (1,0) [0|0] ""  VCU
 SG_ Cell_OV_100 m8 : 23|1@0+ (1,0) [0|0] ""  VCU
 SG_ Cell_UV_100 m8 : 22|1@0+ (1,0) [0|0] ""  VCU
 SG_ Cell_OV_099 m8 : 21|1@0+ (1,0) [0|0] ""  VCU
 SG_ Cell_UV_099 m8 : 20|1@0+ (1,0) [0|0] ""  VCU
 SG_ Cell_OV_098 m8 : 19|1@0+ (1,0) [0|0] ""  VCU
 SG_ Cell_UV_098 m8 : 18|1@0+ (1,0) [0|0] ""  VCU
 SG_ Cell_OV_097 m8 : 17|1@0+ (1,0) [0|0] ""  VCU
 SG_ Cell_UV_097 m8 : 16|1@0+ (1,0) [0|0] ""  VCU
 SG_ Cell_OV_096 m7 : 39|1@0+ (1,0) [0|0] ""  VCU
 SG_ Cell_UV_096 m7 : 38|1@0+ (1,0) [0|0] ""  VCU
 SG_ Cell_OV_095 m7 : 37|1@0+ (1,0) [0|0] ""  VCU
 SG_ Cell_UV_095 m7 : 36|1@0+ (1,0) [0|0] ""  VCU
 SG_ Cell_OV_094 m7 : 35|1@0+ (1,0) [0|0] ""  VCU
 SG_ Cell_UV_094 m7 : 34|1@0+ (1,0) [0|0] ""  VCU
 SG_ Cell_OV_093 m7 : 33|1@0+ (1,0) [0|0] ""  VCU
 SG_ Cell_UV_093 m7 : 32|1@0+ (1,0) [0|0] ""  VCU
 SG_ Cell_OV_092 m7 : 31|1@0+ (1,0) [0|0] ""  VCU
 SG_ Cell_UV_092 m7 : 30|1@0+ (1,0) [0|0] ""  VCU
 SG_ Cell_OV_091 m7 : 29|1@0+ (1,0) [0|0] ""  VCU
 SG_ Cell_UV_091 m7 : 28|1@0+ (1,0) [0|0] ""  VCU
 SG_ Cell_OV_090 m7 : 27|1@0+ (1,0) [0|0] ""  VCU
 SG_ Cell_UV_090 m7 : 26|1@0+ (1,0) [0|0] ""  VCU
 SG_ Cell_OV_089 m7 : 25|1@0+ (1,0) [0|0] ""  VCU
 SG_ Cell_UV_089 m7 : 24|1@0+ (1,0) [0|0] ""  VCU
 SG_ Cell_OV_088 m7 : 23|1@0+ (1,0) [0|0] ""  VCU
 SG_ Cell_UV_088 m7 : 22|1@0+ (1,0) [0|0] ""  VCU
 SG_ Cell_OV_087 m7 : 21|1@0+ (1,0) [0|0] ""  VCU
 SG_ Cell_UV_087 m7 : 20|1@0+ (1,0) [0|0] ""  VCU
 SG_ Cell_OV_086 m7 : 19|1@0+ (1,0) [0|0] ""  VCU
 SG_ Cell_UV_086 m7 : 18|1@0+ (1,0) [0|0] ""  VCU
 SG_ Cell_OV_085 m7 : 17|1@0+ (1,0) [0|0] ""  VCU
 SG_ Cell_UV_085 m7 : 16|1@0+ (1,0) [0|0] ""  VCU
 SG_ Cell_OV_084 m6 : 39|1@0+ (1,0) [0|0] ""  VCU
 SG_ Cell_UV_084 m6 : 38|1@0+ (1,0) [0|0] ""  VCU
 SG_ Cell_OV_083 m6 : 37|1@0+ (1,0) [0|0] ""  VCU
 SG_ Cell_UV_083 m6 : 36|1@0+ (1,0) [0|0] ""  VCU
 SG_ Cell_OV_082 m6 : 35|1@0+ (1,0) [0|0] ""  VCU
 SG_ Cell_UV_082 m6 : 34|1@0+ (1,0) [0|0] ""  VCU
 SG_ Cell_OV_081 m6 : 33|1@0+ (1,0) [0|0] ""  VCU
 SG_ Cell_UV_081 m6 : 32|1@0+ (1,0) [0|0] ""  VCU
 SG_ Cell_OV_080 m6 : 31|1@0+ (1,0) [0|0] ""  VCU
 SG_ Cell_UV_080 m6 : 30|1@0+ (1,0) [0|0] ""  VCU
 SG_ Cell_OV_079 m6 : 29|1@0+ (1,0) [0|0] ""  VCU
 SG_ Cell_UV_079 m6 : 28|1@0+ (1,0) [0|0] ""  VCU
 SG_ Cell_OV_078 m6 : 27|1@0+ (1,0) [0|0] ""  VCU
 SG_ Cell_UV_078 m6 : 26|1@0+ (1,0) [0|0] ""  VCU
 SG_ Cell_OV_077 m6 : 25|1@0+ (1,0) [0|0] ""  VCU
 SG_ Cell_UV_077 m6 : 24|1@0+ (1,0) [0|0] ""  VCU
 SG_ Cell_OV_076 m6 : 23|1@0+ (1,0) [0|0] ""  VCU
 SG_ Cell_UV_076 m6 : 22|1@0+ (1,0) [0|0] ""  VCU
 SG_ Cell_OV_075 m6 : 21|1@0+ (1,0) [0|0] ""  VCU
 SG_ Cell_UV_075 m6 : 20|1@0+ (1,0) [0|0] ""  VCU
 SG_ Cell_OV_074 m6 : 19|1@0+ (1,0) [0|0] ""  VCU
 SG_ Cell_UV_074 m6 : 18|1@0+ (1,0) [0|0] ""  VCU
 SG_ Cell_OV_073 m6 : 17|1@0+ (1,0) [0|0] ""  VCU
 SG_ Cell_UV_073 m6 : 16|1@0+ (1,0) [0|0] ""  VCU
 SG_ Cell_OV_072 m5 : 39|1@0+ (1,0) [0|0] ""  VCU
 SG_ Cell_UV_072 m5 : 38|1@0+ (1,0) [0|0] ""  VCU
 SG_ Cell_OV_071 m5 : 37|1@0+ (1,0) [0|0] ""  VCU
 SG_ Cell_UV_071 m5 : 36|1@0+ (1,0) [0|0] ""  VCU
 SG_ Cell_OV_070 m5 : 35|1@0+ (1,0) [0|0] ""  VCU
 SG_ Cell_UV_070 m5 : 34|1@0+ (1,0) [0|0] ""  VCU
 SG_ Cell_OV_069 m5 : 33|1@0+ (1,0) [0|0] ""  VCU
 SG_ Cell_UV_069 m5 : 32|1@0+ (1,0) [0|0] ""  VCU
 SG_ Cell_OV_068 m5 : 31|1@0+ (1,0) [0|0] ""  VCU
 SG_ Cell_UV_068 m5 : 30|1@0+ (1,0) [0|0] ""  VCU
 SG_ Cell_OV_067 m5 : 29|1@0+ (1,0) [0|0] ""  VCU
 SG_ Cell_UV_067 m5 : 28|1@0+ (1,0) [0|0] ""  VCU
 SG_ Cell_OV_066 m5 : 27|1@0+ (1,0) [0|0] ""  VCU
 SG_ Cell_UV_066 m5 : 26|1@0+ (1,0) [0|0] ""  VCU
 SG_ Cell_OV_065 m5 : 25|1@0+ (1,0) [0|0] ""  VCU
 SG_ Cell_UV_065 m5 : 24|1@0+ (1,0) [0|0] ""  VCU
 SG_ Cell_OV_064 m5 : 23|1@0+ (1,0) [0|0] ""  VCU
 SG_ Cell_UV_064 m5 : 22|1@0+ (1,0) [0|0] ""  VCU
 SG_ Cell_OV_063 m5 : 21|1@0+ (1,0) [0|0] ""  VCU
 SG_ Cell_UV_063 m5 : 20|1@0+ (1,0) [0|0] ""  VCU
 SG_ Cell_OV_062 m5 : 19|1@0+ (1,0) [0|0] ""  VCU
 SG_ Cell_UV_062 m5 : 18|1@0+ (1,0) [0|0] ""  VCU
 SG_ Cell_OV_061 m5 : 17|1@0+ (1,0) [0|0] ""  VCU
 SG_ Cell_UV_061 m5 : 16|1@0+ (1,0) [0|0] ""  VCU
 SG_ Cell_OV_060 m4 : 39|1@0+ (1,0) [0|0] ""  VCU
 SG_ Cell_UV_060 m4 : 38|1@0+ (1,0) [0|0] ""  VCU
 SG_ Cell_OV_059 m4 : 37|1@0+ (1,0) [0|0] ""  VCU
 SG_ Cell_UV_059 m4 : 36|1@0+ (1,0) [0|0] ""  VCU
 SG_ Cell_OV_058 m4 : 35|1@0+ (1,0) [0|0] ""  VCU
 SG_ Cell_UV_058 m4 : 34|1@0+ (1,0) [0|0] ""  VCU
 SG_ Cell_OV_057 m4 : 33|1@0+ (1,0) [0|0] ""  VCU
 SG_ Cell_UV_057 m4 : 32|1@0+ (1,0) [0|0] ""  VCU
 SG_ Cell_OV_056 m4 : 31|1@0+ (1,0) [0|0] ""  VCU
 SG_ Cell_UV_056 m4 : 30|1@0+ (1,0) [0|0] ""  VCU
 SG_ Cell_OV_055 m4 : 29|1@0+ (1,0) [0|0] ""  VCU
 SG_ Cell_UV_055 m4 : 28|1@0+ (1,0) [0|0] ""  VCU
 SG_ Cell_OV_054 m4 : 27|1@0+ (1,0) [0|0] ""  VCU
 SG_ Cell_UV_054 m4 : 26|1@0+ (1,0) [0|0] ""  VCU
 SG_ Cell_OV_053 m4 : 25|1@0+ (1,0) [0|0] ""  VCU
 SG_ Cell_UV_053 m4 : 24|1@0+ (1,0) [0|0] ""  VCU
 SG_ Cell_OV_052 m4 : 23|1@0+ (1,0) [0|0] ""  VCU
 SG_ Cell_UV_052 m4 : 22|1@0+ (1,0) [0|0] ""  VCU
 SG_ Cell_OV_051 m4 : 21|1@0+ (1,0) [0|0] ""  VCU
 SG_ Cell_UV_051 m4 : 20|1@0+ (1,0) [0|0] ""  VCU
 SG_ Cell_OV_050 m4 : 19|1@0+ (1,0) [0|0] ""  VCU
 SG_ Cell_UV_050 m4 : 18|1@0+ (1,0) [0|0] ""  VCU
 SG_ Cell_OV_049 m4 : 17|1@0+ (1,0) [0|0] ""  VCU
 SG_ Cell_UV_049 m4 : 16|1@0+ (1,0) [0|0] ""  VCU
 SG_ Cell_OV_048 m3 : 39|1@0+ (1,0) [0|0] ""  VCU
 SG_ Cell_UV_048 m3 : 38|1@0+ (1,0) [0|0] ""  VCU
 SG_ Cell_OV_047 m3 : 37|1@0+ (1,0) [0|0] ""  VCU
 SG_ Cell_UV_047 m3 : 36|1@0+ (1,0) [0|0] ""  VCU
 SG_ Cell_OV_046 m3 : 35|1@0+ (1,0) [0|0] ""  VCU
 SG_ Cell_UV_046 m3 : 34|1@0+ (1,0) [0|0] ""  VCU
 SG_ Cell_OV_045 m3 : 33|1@0+ (1,0) [0|0] ""  VCU
 SG_ Cell_UV_045 m3 : 32|1@0+ (1,0) [0|0] ""  VCU
 SG_ Cell_OV_044 m3 : 31|1@0+ (1,0) [0|0] ""  VCU
 SG_ Cell_UV_044 m3 : 30|1@0+ (1,0) [0|0] ""  VCU
 SG_ Cell_OV_043 m3 : 29|1@0+ (1,0) [0|0] ""  VCU
 SG_ Cell_UV_043 m3 : 28|1@0+ (1,0) [0|0] ""  VCU
 SG_ Cell_OV_042 m3 : 27|1@0+ (1,0) [0|0] ""  VCU
 SG_ Cell_UV_042 m3 : 26|1@0+ (1,0) [0|0] ""  VCU
 SG_ Cell_OV_041 m3 : 25|1@0+ (1,0) [0|0] ""  VCU
 SG_ Cell_UV_041 m3 : 24|1@0+ (1,0) [0|0] ""  VCU
 SG_ Cell_OV_040 m3 : 23|1@0+ (1,0) [0|0] ""  VCU
 SG_ Cell_UV_040 m3 : 22|1@0+ (1,0) [0|0] ""  VCU
 SG_ Cell_OV_039 m3 : 21|1@0+ (1,0) [0|0] ""  VCU
 SG_ Cell_UV_039 m3 : 20|1@0+ (1,0) [0|0] ""  VCU
 SG_ Cell_OV_038 m3 : 19|1@0+ (1,0) [0|0] ""  VCU
 SG_ Cell_UV_038 m3 : 18|1@0+ (1,0) [0|0] ""  VCU
 SG_ Cell_OV_037 m3 : 17|1@0+ (1,0) [0|0] ""  VCU
 SG_ Cell_UV_037 m3 : 16|1@0+ (1,0) [0|0] ""  VCU
 SG_ Cell_OV_036 m2 : 39|1@0+ (1,0) [0|0] ""  VCU
 SG_ Cell_UV_036 m2 : 38|1@0+ (1,0) [0|0] ""  VCU
 SG_ Cell_OV_035 m2 : 37|1@0+ (1,0) [0|0] ""  VCU
 SG_ Cell_UV_035 m2 : 36|1@0+ (1,0) [0|0] ""  VCU
 SG_ Cell_OV_034 m2 : 35|1@0+ (1,0) [0|0] ""  VCU
 SG_ Cell_UV_034 m2 : 34|1@0+ (1,0) [0|0] ""  VCU
 SG_ Cell_OV_033 m2 : 33|1@0+ (1,0) [0|0] ""  VCU
 SG_ Cell_UV_033 m2 : 32|1@0+ (1,0) [0|0] ""  VCU
 SG_ Cell_OV_032 m2 : 31|1@0+ (1,0) [0|0] ""  VCU
 SG_ Cell_UV_032 m2 : 30|1@0+ (1,0) [0|0] ""  VCU
 SG_ Cell_OV_031 m2 : 29|1@0+ (1,0) [0|0] ""  VCU
 SG_ Cell_UV_031 m2 : 28|1@0+ (1,0) [0|0] ""  VCU
 SG_ Cell_OV_030 m2 : 27|1@0+ (1,0) [0|0] ""  VCU
 SG_ Cell_UV_030 m2 : 26|1@0+ (1,0) [0|0] ""  VCU
 SG_ Cell_OV_029 m2 : 25|1@0+ (1,0) [0|0] ""  VCU
 SG_ Cell_UV_029 m2 : 24|1@0+ (1,0) [0|0] ""  VCU
 SG_ Cell_OV_028 m2 : 23|1@0+ (1,0) [0|0] ""  VCU
 SG_ Cell_UV_028 m2 : 22|1@0+ (1,0) [0|0] ""  VCU
 SG_ Cell_OV_027 m2 : 21|1@0+ (1,0) [0|0] ""  VCU
 SG_ Cell_UV_027 m2 : 20|1@0+ (1,0) [0|0] ""  VCU
 SG_ Cell_OV_026 m2 : 19|1@0+ (1,0) [0|0] ""  VCU
 SG_ Cell_UV_026 m2 : 18|1@0+ (1,0) [0|0] ""  VCU
 SG_ Cell_OV_025 m2 : 17|1@0+ (1,0) [0|0] ""  VCU
 SG_ Cell_UV_025 m2 : 16|1@0+ (1,0) [0|0] ""  VCU
 SG_ Cell_OV_024 m1 : 39|1@0+ (1,0) [0|0] ""  VCU
 SG_ Cell_UV_024 m1 : 38|1@0+ (1,0) [0|0] ""  VCU
 SG_ Cell_OV_023 m1 : 37|1@0+ (1,0) [0|0] ""  VCU
 SG_ Cell_UV_023 m1 : 36|1@0+ (1,0) [0|0] ""  VCU
 SG_ Cell_OV_022 m1 : 35|1@0+ (1,0) [0|0] ""  VCU
 SG_ Cell_UV_022 m1 : 34|1@0+ (1,0) [0|0] ""  VCU
 SG_ Cell_OV_021 m1 : 33|1@0+ (1,0) [0|0] ""  VCU
 SG_ Cell_UV_021 m1 : 32|1@0+ (1,0) [0|0] ""  VCU
 SG_ Cell_OV_020 m1 : 31|1@0+ (1,0) [0|0] ""  VCU
 SG_ Cell_UV_020 m1 : 30|1@0+ (1,0) [0|0] ""  VCU
 SG_ Cell_OV_019 m1 : 29|1@0+ (1,0) [0|0] ""  VCU
 SG_ Cell_UV_019 m1 : 28|1@0+ (1,0) [0|0] ""  VCU
 SG_ Cell_OV_018 m1 : 27|1@0+ (1,0) [0|0] ""  VCU
 SG_ Cell_UV_018 m1 : 26|1@0+ (1,0) [0|0] ""  VCU
 SG_ Cell_OV_017 m1 : 25|1@0+ (1,0) [0|0] ""  VCU
 SG_ Cell_UV_017 m1 : 24|1@0+ (1,0) [0|0] ""  VCU
 SG_ Cell_OV_016 m1 : 23|1@0+ (1,0) [0|0] ""  VCU
 SG_ Cell_UV_016 m1 : 22|1@0+ (1,0) [0|0] ""  VCU
 SG_ Cell_OV_015 m1 : 21|1@0+ (1,0) [0|0] ""  VCU
 SG_ Cell_UV_015 m1 : 20|1@0+ (1,0) [0|0] ""  VCU
 SG_ Cell_OV_014 m1 : 19|1@0+ (1,0) [0|0] ""  VCU
 SG_ Cell_UV_014 m1 : 18|1@0+ (1,0) [0|0] ""  VCU
 SG_ Cell_OV_013 m1 : 17|1@0+ (1,0) [0|0] ""  VCU
 SG_ Cell_UV_013 m1 : 16|1@0+ (1,0) [0|0] ""  VCU
 SG_ Cell_OV_012 m0 : 39|1@0+ (1,0) [0|0] ""  VCU
 SG_ Cell_UV_012 m0 : 38|1@0+ (1,0) [0|0] ""  VCU
 SG_ Cell_OV_011 m0 : 37|1@0+ (1,0) [0|0] ""  VCU
 SG_ Cell_UV_011 m0 : 36|1@0+ (1,0) [0|0] ""  VCU
 SG_ Cell_OV_010 m0 : 35|1@0+ (1,0) [0|0] ""  VCU
 SG_ Cell_UV_010 m0 : 34|1@0+ (1,0) [0|0] ""  VCU
 SG_ Cell_OV_009 m0 : 33|1@0+ (1,0) [0|0] ""  VCU
 SG_ Cell_UV_009 m0 : 32|1@0+ (1,0) [0|0] ""  VCU
 SG_ Cell_OV_008 m0 : 31|1@0+ (1,0) [0|0] ""  VCU
 SG_ Cell_UV_008 m0 : 30|1@0+ (1,0) [0|0] ""  VCU
 SG_ Cell_OV_007 m0 : 29|1@0+ (1,0) [0|0] ""  VCU
 SG_ Cell_UV_007 m0 : 28|1@0+ (1,0) [0|0] ""  VCU
 SG_ Cell_OV_006 m0 : 27|1@0+ (1,0) [0|0] ""  VCU
 SG_ Cell_UV_006 m0 : 26|1@0+ (1,0) [0|0] ""  VCU
 SG_ Cell_OV_005 m0 : 25|1@0+ (1,0) [0|0] ""  VCU
 SG_ Cell_UV_005 m0 : 24|1@0+ (1,0) [0|0] ""  VCU
 SG_ Cell_OV_004 m0 : 23|1@0+ (1,0) [0|0] ""  VCU
 SG_ Cell_UV_004 m0 : 22|1@0+ (1,0) [0|0] ""  VCU
 SG_ Cell_OV_003 m0 : 21|1@0+ (1,0) [0|0] ""  VCU
 SG_ Cell_UV_003 m0 : 20|1@0+ (1,0) [0|0] ""  VCU
 SG_ Cell_OV_002 m0 : 19|1@0+ (1,0) [0|0] ""  VCU
 SG_ Cell_UV_002 m0 : 18|1@0+ (1,0) [0|0] ""  VCU
 SG_ Cell_OV_001 m0 : 17|1@0+ (1,0) [0|0] ""  VCU
 SG_ Cell_UV_001 m0 : 16|1@0+ (1,0) [0|0] ""  VCU
 SG_ error_U_detected : 1|1@0+ (1,0) [0|0] ""  VCU
 SG_ error_T_detected : 0|1@0+ (1,0) [0|0] ""  VCU
 SG_ Connection2Slaves : 2|1@0+ (1,0) [0|0] ""  VCU
 SG_ Hauptschuetze_geschlossen : 3|1@0+ (1,0) [0|0] ""  VCU
 SG_ Ladevorgang_aktiv : 4|1@0+ (1,0) [0|0] ""  VCU
 SG_ Balancing_aktiv : 5|1@0+ (1,0) [0|0] ""  VCU
 SG_ Multiplexor_AMS_Status M : 15|8@0+ (1,0) [0|255] ""  VCU
 SG_ Global_Enable_Flag : 7|1@0+ (1,0) [0|1] ""  VCU

BO_ 514 AMS_Alive: 4 AMS
 SG_ AMS_Alive_Counter : 7|32@0+ (1,0) [0|0] ""  VCU

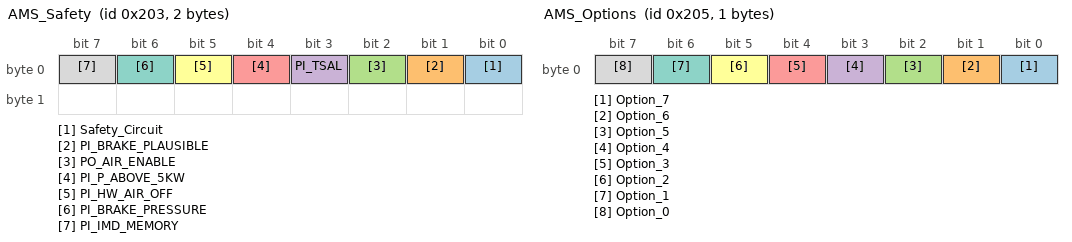
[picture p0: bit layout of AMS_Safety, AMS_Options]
BO_ 515 AMS_Safety: 2 AMS
 SG_ Safety_Circuit : 0|1@0+ (1,0) [0|0] ""  VCU
 SG_ PI_BRAKE_PLAUSIBLE : 1|1@0+ (1,0) [0|0] ""  VCU
 SG_ PO_AIR_ENABLE : 2|1@0+ (1,0) [0|0] ""  VCU
 SG_ PI_TSAL : 3|1@0+ (1,0) [0|0] ""  VCU
 SG_ PI_P_ABOVE_5KW : 4|1@0+ (1,0) [0|0] ""  VCU
 SG_ PI_HW_AIR_OFF : 5|1@0+ (1,0) [0|0] ""  VCU
 SG_ PI_BRAKE_PRESSURE : 6|1@0+ (1,0) [0|0] ""  VCU
 SG_ PI_IMD_MEMORY : 7|1@0+ (1,0) [0|0] ""  VCU

BO_ 517 AMS_Options: 1 AMS
 SG_ Option_7 : 0|1@0+ (1,0) [0|0] ""  VCU
 SG_ Option_6 : 1|1@0+ (1,0) [0|0] ""  VCU
 SG_ Option_5 : 2|1@0+ (1,0) [0|0] ""  VCU
 SG_ Option_4 : 3|1@0+ (1,0) [0|0] ""  VCU
 SG_ Option_3 : 4|1@0+ (1,0) [0|0] ""  VCU
 SG_ Option_2 : 5|1@0+ (1,0) [0|0] ""  VCU
 SG_ Option_1 : 6|1@0+ (1,0) [0|0] ""  VCU
 SG_ Option_0 : 7|1@0+ (1,0) [0|0] ""  VCU

BO_ 561 VCU_Alive: 1 VCU
 SG_ VCU_Alive_Signal : 0|1@0+ (1,0) [0|0] ""  AMS

BO_ 562 VCU_Cmd_AmsOptions1: 1 VCU
 SG_ HVFan_ON : 0|1@0+ (1,0) [0|0] ""  AMS

BO_ 656 TorqueAndBreak: 2 PIC
 SG_ BreakPressure : 15|8@0+ (0.39216,0) [0|100.0008] ""  VCU
 SG_ Torque : 7|8@0+ (0.39216,0) [0|100.0008] ""  VCU

BO_ 800 SS_CMD_BrakeLight: 1 VCU
 SG_ BrakeLight_ON : 0|1@0+ (1,0) [0|0] ""  SS_BL

BO_ 801 SS_CMD_RTDS: 1 VCU
 SG_ RTDS_ON : 0|1@0+ (1,0) [0|0] ""  SS_RTDS

BO_ 802 SS_CMD_WaterPump1: 1 VCU
 SG_ WaterPump1_ON : 0|1@0+ (1,0) [0|0] ""  SS_WP1

BO_ 803 SS_CMD_WaterPump2: 1 VCU
 SG_ WaterPump2_ON : 0|1@0+ (1,0) [0|0] ""  SS_WP2

BO_ 848 SS_Deflection_FL: 2 SS_DFL
 SG_ DeflectionFrontLeft : 7|16@0- (1,0) [0|0] ""  VCU

BO_ 849 SS_Deflection_FR: 2 SS_DFR
 SG_ DeflectionFrontRight : 7|16@0- (1,0) [0|0] ""  VCU

BO_ 850 SS_Deflection_BL: 2 SS_DBL
 SG_ DeflectionBackLeft : 7|16@0- (1,0) [0|0] ""  VCU

BO_ 851 SS_Deflection_BR: 2 SS_DBR
 SG_ DeflectionBackRight : 7|16@0- (1,0) [0|0] ""  VCU

BO_ 852 SS_SteeringAngle: 2 SteeringWheel
 SG_ SteeringAngle : 0|16@1- (1,0) [-32768|32767] ""  VCU

BO_ 864 SS_WaterTemp1: 1 SS_WT1
 SG_ TemperatureWater1 : 7|8@0+ (1,0) [0|255] ""  VCU

BO_ 865 SS_WaterTemp2: 1 SS_WT2
 SG_ TemperatureWater2 : 7|8@0+ (1,0) [0|255] ""  VCU

BO_ 866 SS_WaterTemp3: 1 SS_WT3
 SG_ TemperatureWater3 : 7|8@0+ (1,0) [0|255] ""  VCU

BO_ 867 SS_WaterTemp4: 1 SS_WT4
 SG_ TemperatureWater4 : 7|8@0+ (1,0) [0|255] ""  VCU

BO_ 868 SS_WaterPump1: 1 SS_WP1
 SG_ WaterPump1_State : 0|1@0+ (1,0) [0|0] ""  VCU

BO_ 869 SS_WaterPump2: 1 SS_WP2
 SG_ WaterPump2_State : 0|1@0+ (1,0) [0|0] ""  VCU

CM_ BU_ SS_WT4 "SmartSensor Water Temperature 4";
CM_ BU_ SS_WT3 "SmartSensor Water Temperature 3";
CM_ BU_ SS_WT2 "SmartSensor Water Temperature 2";
CM_ BU_ SS_WT1 "SmartSensor Water Temperature 1";
CM_ BU_ SS_WP2 "SmartSensor Water Pump 2";
CM_ BU_ SS_WP1 "SmartSensor Water Pump 1";
CM_ BU_ SS_WF "SmartSensor Water Flow";
CM_ BU_ SS_SA "SmartSensor steering angle";
CM_ BU_ SS_RTDS "SmartSensor ready to drive sound";
CM_ BU_ SS_DFR "SmartSensor Deflection Front Right";
CM_ BU_ SS_DFL "SmartSensor Deflection Front Left";
CM_ BU_ SS_DBR "Smart Sensor Deflection Back Right";
CM_ BU_ SS_DBL "SmartSensor Deflection Back Left";
CM_ BU_ User "extern developer eg. with CANoe";
CM_ BU_ SS_BL "SmartSensor Brake Light";
CM_ BU_ PIC "Pedalerie Platine (IC - integrated circuit)";
CM_ BU_ ISA_Scale "ISA Scale - Stromsensor";
VAL_ 561 VCU_Alive_Signal 1 "ONLINE" 0 "OFFLINE" ;
